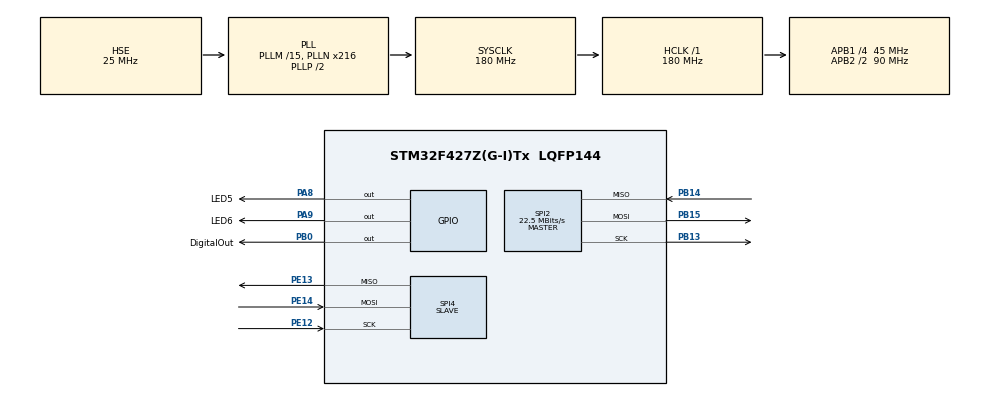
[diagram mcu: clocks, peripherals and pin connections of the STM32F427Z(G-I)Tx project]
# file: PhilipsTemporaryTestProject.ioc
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Dma.Request0=SPI2_RX
Dma.Request1=SPI2_TX
Dma.Request2=SPI4_RX
Dma.Request3=SPI4_TX
Dma.SPI2_RX.0.Direction=DMA_PERIPH_TO_MEMORY
Dma.SPI2_RX.0.FIFOMode=DMA_FIFOMODE_DISABLE
Dma.SPI2_RX.0.Instance=DMA1_Stream3
Dma.SPI2_RX.0.MemDataAlignment=DMA_MDATAALIGN_BYTE
Dma.SPI2_RX.0.MemInc=DMA_MINC_ENABLE
Dma.SPI2_RX.0.Mode=DMA_NORMAL
Dma.SPI2_RX.0.PeriphDataAlignment=DMA_PDATAALIGN_BYTE
Dma.SPI2_RX.0.PeriphInc=DMA_PINC_DISABLE
Dma.SPI2_RX.0.Priority=DMA_PRIORITY_LOW
Dma.SPI2_TX.1.Direction=DMA_MEMORY_TO_PERIPH
Dma.SPI2_TX.1.FIFOMode=DMA_FIFOMODE_DISABLE
Dma.SPI2_TX.1.Instance=DMA1_Stream4
Dma.SPI2_TX.1.MemDataAlignment=DMA_MDATAALIGN_BYTE
Dma.SPI2_TX.1.MemInc=DMA_MINC_ENABLE
Dma.SPI2_TX.1.Mode=DMA_NORMAL
Dma.SPI2_TX.1.PeriphDataAlignment=DMA_PDATAALIGN_BYTE
Dma.SPI2_TX.1.PeriphInc=DMA_PINC_DISABLE
Dma.SPI2_TX.1.Priority=DMA_PRIORITY_LOW
Dma.SPI4_RX.2.Direction=DMA_PERIPH_TO_MEMORY
Dma.SPI4_RX.2.FIFOMode=DMA_FIFOMODE_DISABLE
Dma.SPI4_RX.2.Instance=DMA2_Stream0
Dma.SPI4_RX.2.MemDataAlignment=DMA_MDATAALIGN_BYTE
Dma.SPI4_RX.2.MemInc=DMA_MINC_ENABLE
Dma.SPI4_RX.2.Mode=DMA_NORMAL
Dma.SPI4_RX.2.PeriphDataAlignment=DMA_PDATAALIGN_BYTE
Dma.SPI4_RX.2.PeriphInc=DMA_PINC_DISABLE
Dma.SPI4_RX.2.Priority=DMA_PRIORITY_LOW
Dma.SPI4_TX.3.Direction=DMA_MEMORY_TO_PERIPH
Dma.SPI4_TX.3.FIFOMode=DMA_FIFOMODE_DISABLE
Dma.SPI4_TX.3.Instance=DMA2_Stream1
Dma.SPI4_TX.3.MemDataAlignment=DMA_MDATAALIGN_BYTE
Dma.SPI4_TX.3.MemInc=DMA_MINC_ENABLE
Dma.SPI4_TX.3.Mode=DMA_NORMAL
Dma.SPI4_TX.3.PeriphDataAlignment=DMA_PDATAALIGN_BYTE
Dma.SPI4_TX.3.PeriphInc=DMA_PINC_DISABLE
Dma.SPI4_TX.3.Priority=DMA_PRIORITY_LOW
Mcu.Family=STM32F4
Mcu.Name=STM32F427Z(G-I)Tx
Mcu.Package=LQFP144
NVIC.DMA1_Stream3_IRQn=true\:0\:0\:false\:false\:true\:false\:true
NVIC.DMA1_Stream4_IRQn=true\:0\:0\:false\:false\:true\:false\:true
NVIC.DMA2_Stream0_IRQn=true\:0\:0\:false\:false\:true\:false\:true
NVIC.DMA2_Stream1_IRQn=true\:0\:0\:false\:false\:true\:false\:true
NVIC.PriorityGroup=NVIC_PRIORITYGROUP_4
PA8.GPIO_Label=LED5
PA8.Signal=GPIO_Output
PA9.GPIO_Label=LED6
PA9.Signal=GPIO_Output
PB0.GPIO_Label=DigitalOut
PB0.Signal=GPIO_Output
PB13.Mode=Full_Duplex_Master
PB13.Signal=SPI2_SCK
PB14.Mode=Full_Duplex_Master
PB14.Signal=SPI2_MISO
PB15.Mode=Full_Duplex_Master
PB15.Signal=SPI2_MOSI
PC14/OSC32_IN.Mode=LSE-External-Oscillator
PC14/OSC32_IN.Signal=RCC_OSC32_IN
PC15/OSC32_OUT.Mode=LSE-External-Oscillator
PC15/OSC32_OUT.Signal=RCC_OSC32_OUT
PE12.Mode=Full_Duplex_Slave
PE12.Signal=SPI4_SCK
PE13.Mode=Full_Duplex_Slave
PE13.Signal=SPI4_MISO
PE14.Mode=Full_Duplex_Slave
PE14.Signal=SPI4_MOSI
PH0/OSC_IN.Mode=HSE-External-Oscillator
PH0/OSC_IN.Signal=RCC_OSC_IN
PH1/OSC_OUT.Mode=HSE-External-Oscillator
PH1/OSC_OUT.Signal=RCC_OSC_OUT
ProjectManager.HeapSize=0x200
ProjectManager.StackSize=0x400
ProjectManager.TargetToolchain=STM32CubeIDE
RCC.48MHZClocksFreq_Value=90000000
RCC.AHBFreq_Value=180000000
RCC.APB1CLKDivider=RCC_HCLK_DIV4
RCC.APB1Freq_Value=45000000
RCC.APB1TimFreq_Value=90000000
RCC.APB2CLKDivider=RCC_HCLK_DIV2
RCC.APB2Freq_Value=90000000
RCC.APB2TimFreq_Value=180000000
RCC.CortexFreq_Value=180000000
RCC.HCLKFreq_Value=180000000
RCC.HSE_VALUE=25000000
RCC.HSICalibrationValue=25
RCC.HSI_VALUE=16000000
RCC.PLLM=15
RCC.PLLN=216
RCC.PLLSourceVirtual=RCC_PLLSOURCE_HSE
RCC.SYSCLKFreq_VALUE=180000000
RCC.SYSCLKSource=RCC_SYSCLKSOURCE_PLLCLK
RCC.VCOOutputFreq_Value=360000000
SPI2.CalculateBaudRate=22.5 MBits/s
SPI2.Direction=SPI_DIRECTION_2LINES
SPI2.Mode=SPI_MODE_MASTER
SPI2.VirtualType=VM_MASTER
SPI4.Direction=SPI_DIRECTION_2LINES
SPI4.Mode=SPI_MODE_SLAVE
SPI4.VirtualType=VM_SLAVE
board=custom

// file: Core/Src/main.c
/* USER CODE BEGIN Header */
/**
  ******************************************************************************
  * @file           : main.c
  * @brief          : Main program body
  ******************************************************************************
  * @attention
  *
  * <h2><center>&copy; Copyright (c) 2020 STMicroelectronics.
  * All rights reserved.</center></h2>
  *
  * This software component is licensed by ST under BSD 3-Clause license,
  * the "License"; You may not use this file except in compliance with the
  * License. You may obtain a copy of the License at:
  *                        opensource.org/licenses/BSD-3-Clause
  *
  ******************************************************************************
  */
/* USER CODE END Header */

#include "main.h"

SPI_HandleTypeDef hspi2;
SPI_HandleTypeDef hspi4;
DMA_HandleTypeDef hdma_spi2_rx;
DMA_HandleTypeDef hdma_spi2_tx;
DMA_HandleTypeDef hdma_spi4_rx;
DMA_HandleTypeDef hdma_spi4_tx;

void SystemClock_Config(void);
static void MX_GPIO_Init(void);
static void MX_DMA_Init(void);
static void MX_SPI2_Init(void);
static void MX_SPI4_Init(void);

int main(void)
{

  /* MCU Configuration--------------------------------------------------------*/

  /* Reset of all peripherals, Initializes the Flash interface and the Systick. */
  HAL_Init();

  /* Configure the system clock */
  SystemClock_Config();

  /* Initialize all configured peripherals */
  MX_GPIO_Init();
  MX_DMA_Init();
  MX_SPI2_Init();
  MX_SPI4_Init();
  /* USER CODE BEGIN 2 */
  SPI2->CR1 |= SPI_CR1_SPE;
  /* USER CODE END 2 */

  /* Infinite loop */
  /* USER CODE BEGIN WHILE */
  HAL_GPIO_WritePin(LED5_GPIO_Port, LED5_Pin, GPIO_PIN_SET);

	uint8_t buffer[400];
	uint8_t dummy_buffer[400];
	for(uint8_t i=0; i<100; i++)
	  *((float *)(buffer+4*i)) = 0.5*i;
	HAL_SPI_TransmitReceive_DMA(&hspi4, buffer, dummy_buffer, 400);
	HAL_GPIO_TogglePin(LED6_GPIO_Port, LED6_Pin);

  while (1)
  {
    /* USER CODE END WHILE */
  }
}

void SystemClock_Config(void)
{
  RCC_OscInitTypeDef RCC_OscInitStruct = {0};
  RCC_ClkInitTypeDef RCC_ClkInitStruct = {0};

  /** Configure the main internal regulator output voltage
  */
  __HAL_RCC_PWR_CLK_ENABLE();
  __HAL_PWR_VOLTAGESCALING_CONFIG(PWR_REGULATOR_VOLTAGE_SCALE1);
  /** Initializes the CPU, AHB and APB busses clocks
  */
  RCC_OscInitStruct.OscillatorType = RCC_OSCILLATORTYPE_HSE;
  RCC_OscInitStruct.HSEState = RCC_HSE_ON;
  RCC_OscInitStruct.PLL.PLLState = RCC_PLL_ON;
  RCC_OscInitStruct.PLL.PLLSource = RCC_PLLSOURCE_HSE;
  RCC_OscInitStruct.PLL.PLLM = 15;
  RCC_OscInitStruct.PLL.PLLN = 216;
  RCC_OscInitStruct.PLL.PLLP = RCC_PLLP_DIV2;
  RCC_OscInitStruct.PLL.PLLQ = 4;
  if (HAL_RCC_OscConfig(&RCC_OscInitStruct) != HAL_OK)
  {
    Error_Handler();
  }
  /** Activate the Over-Drive mode
  */
  if (HAL_PWREx_EnableOverDrive() != HAL_OK)
  {
    Error_Handler();
  }
  /** Initializes the CPU, AHB and APB busses clocks
  */
  RCC_ClkInitStruct.ClockType = RCC_CLOCKTYPE_HCLK|RCC_CLOCKTYPE_SYSCLK
                              |RCC_CLOCKTYPE_PCLK1|RCC_CLOCKTYPE_PCLK2;
  RCC_ClkInitStruct.SYSCLKSource = RCC_SYSCLKSOURCE_PLLCLK;
  RCC_ClkInitStruct.AHBCLKDivider = RCC_SYSCLK_DIV1;
  RCC_ClkInitStruct.APB1CLKDivider = RCC_HCLK_DIV4;
  RCC_ClkInitStruct.APB2CLKDivider = RCC_HCLK_DIV2;

  if (HAL_RCC_ClockConfig(&RCC_ClkInitStruct, FLASH_LATENCY_5) != HAL_OK)
  {
    Error_Handler();
  }
}

static void MX_SPI2_Init(void)
{

  /* SPI2 parameter configuration*/
  hspi2.Instance = SPI2;
  hspi2.Init.Mode = SPI_MODE_MASTER;
  hspi2.Init.Direction = SPI_DIRECTION_2LINES;
  hspi2.Init.DataSize = SPI_DATASIZE_8BIT;
  hspi2.Init.CLKPolarity = SPI_POLARITY_LOW;
  hspi2.Init.CLKPhase = SPI_PHASE_1EDGE;
  hspi2.Init.NSS = SPI_NSS_SOFT;
  hspi2.Init.BaudRatePrescaler = SPI_BAUDRATEPRESCALER_2;
  hspi2.Init.FirstBit = SPI_FIRSTBIT_MSB;
  hspi2.Init.TIMode = SPI_TIMODE_DISABLE;
  hspi2.Init.CRCCalculation = SPI_CRCCALCULATION_DISABLE;
  hspi2.Init.CRCPolynomial = 10;
  if (HAL_SPI_Init(&hspi2) != HAL_OK)
  {
    Error_Handler();
  }

}

static void MX_SPI4_Init(void)
{

  /* SPI4 parameter configuration*/
  hspi4.Instance = SPI4;
  hspi4.Init.Mode = SPI_MODE_SLAVE;
  hspi4.Init.Direction = SPI_DIRECTION_2LINES;
  hspi4.Init.DataSize = SPI_DATASIZE_8BIT;
  hspi4.Init.CLKPolarity = SPI_POLARITY_LOW;
  hspi4.Init.CLKPhase = SPI_PHASE_1EDGE;
  hspi4.Init.NSS = SPI_NSS_SOFT;
  hspi4.Init.FirstBit = SPI_FIRSTBIT_MSB;
  hspi4.Init.TIMode = SPI_TIMODE_DISABLE;
  hspi4.Init.CRCCalculation = SPI_CRCCALCULATION_DISABLE;
  hspi4.Init.CRCPolynomial = 10;
  if (HAL_SPI_Init(&hspi4) != HAL_OK)
  {
    Error_Handler();
  }

}

static void MX_DMA_Init(void)
{

  /* DMA controller clock enable */
  __HAL_RCC_DMA1_CLK_ENABLE();
  __HAL_RCC_DMA2_CLK_ENABLE();

  /* DMA interrupt init */
  /* DMA1_Stream3_IRQn interrupt configuration */
  HAL_NVIC_SetPriority(DMA1_Stream3_IRQn, 0, 0);
  HAL_NVIC_EnableIRQ(DMA1_Stream3_IRQn);
  /* DMA1_Stream4_IRQn interrupt configuration */
  HAL_NVIC_SetPriority(DMA1_Stream4_IRQn, 0, 0);
  HAL_NVIC_EnableIRQ(DMA1_Stream4_IRQn);
  /* DMA2_Stream0_IRQn interrupt configuration */
  HAL_NVIC_SetPriority(DMA2_Stream0_IRQn, 0, 0);
  HAL_NVIC_EnableIRQ(DMA2_Stream0_IRQn);
  /* DMA2_Stream1_IRQn interrupt configuration */
  HAL_NVIC_SetPriority(DMA2_Stream1_IRQn, 0, 0);
  HAL_NVIC_EnableIRQ(DMA2_Stream1_IRQn);

}

static void MX_GPIO_Init(void)
{
  GPIO_InitTypeDef GPIO_InitStruct = {0};

  /* GPIO Ports Clock Enable */
  __HAL_RCC_GPIOC_CLK_ENABLE();
  __HAL_RCC_GPIOH_CLK_ENABLE();
  __HAL_RCC_GPIOB_CLK_ENABLE();
  __HAL_RCC_GPIOE_CLK_ENABLE();
  __HAL_RCC_GPIOA_CLK_ENABLE();

  /*Configure GPIO pin Output Level */
  HAL_GPIO_WritePin(DigitalOut_GPIO_Port, DigitalOut_Pin, GPIO_PIN_RESET);

  /*Configure GPIO pin Output Level */
  HAL_GPIO_WritePin(GPIOA, LED5_Pin|LED6_Pin, GPIO_PIN_RESET);

  /*Configure GPIO pin : DigitalOut_Pin */
  GPIO_InitStruct.Pin = DigitalOut_Pin;
  GPIO_InitStruct.Mode = GPIO_MODE_OUTPUT_PP;
  GPIO_InitStruct.Pull = GPIO_NOPULL;
  GPIO_InitStruct.Speed = GPIO_SPEED_FREQ_LOW;
  HAL_GPIO_Init(DigitalOut_GPIO_Port, &GPIO_InitStruct);

  /*Configure GPIO pins : LED5_Pin LED6_Pin */
  GPIO_InitStruct.Pin = LED5_Pin|LED6_Pin;
  GPIO_InitStruct.Mode = GPIO_MODE_OUTPUT_PP;
  GPIO_InitStruct.Pull = GPIO_NOPULL;
  GPIO_InitStruct.Speed = GPIO_SPEED_FREQ_LOW;
  HAL_GPIO_Init(GPIOA, &GPIO_InitStruct);

}

void Error_Handler(void)
{
}

/************************ (C) COPYRIGHT STMicroelectronics *****END OF FILE****/
